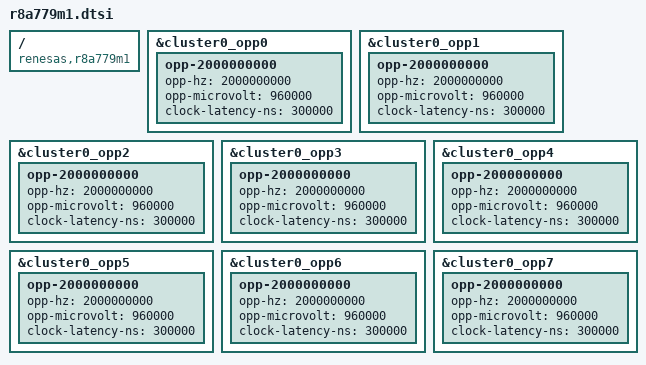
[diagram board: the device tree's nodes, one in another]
// SPDX-License-Identifier: GPL-2.0
/*
 * Device Tree Source for the R-Car H3e-2G (R8A779M1) SoC
 *
 * Copyright (C) 2021 Renesas Electronics Corp.
 */

#include "r8a77951.dtsi"

/ {
	compatible = "renesas,r8a779m1", "renesas,r8a7795";
};

&cluster0_opp0 {
	opp-2000000000 {
		opp-hz = /bits/ 64 <2000000000>;
		opp-microvolt = <960000>;
		clock-latency-ns = <300000>;
	};
};

&cluster0_opp1 {
	opp-2000000000 {
		opp-hz = /bits/ 64 <2000000000>;
		opp-microvolt = <960000>;
		clock-latency-ns = <300000>;
	};
};

&cluster0_opp2 {
	opp-2000000000 {
		opp-hz = /bits/ 64 <2000000000>;
		opp-microvolt = <960000>;
		clock-latency-ns = <300000>;
	};
};

&cluster0_opp3 {
	opp-2000000000 {
		opp-hz = /bits/ 64 <2000000000>;
		opp-microvolt = <960000>;
		clock-latency-ns = <300000>;
	};
};

&cluster0_opp4 {
	opp-2000000000 {
		opp-hz = /bits/ 64 <2000000000>;
		opp-microvolt = <960000>;
		clock-latency-ns = <300000>;
	};
};

&cluster0_opp5 {
	opp-2000000000 {
		opp-hz = /bits/ 64 <2000000000>;
		opp-microvolt = <960000>;
		clock-latency-ns = <300000>;
	};
};

&cluster0_opp6 {
	opp-2000000000 {
		opp-hz = /bits/ 64 <2000000000>;
		opp-microvolt = <960000>;
		clock-latency-ns = <300000>;
	};
};

&cluster0_opp7 {
	opp-2000000000 {
		opp-hz = /bits/ 64 <2000000000>;
		opp-microvolt = <960000>;
		clock-latency-ns = <300000>;
	};
};
